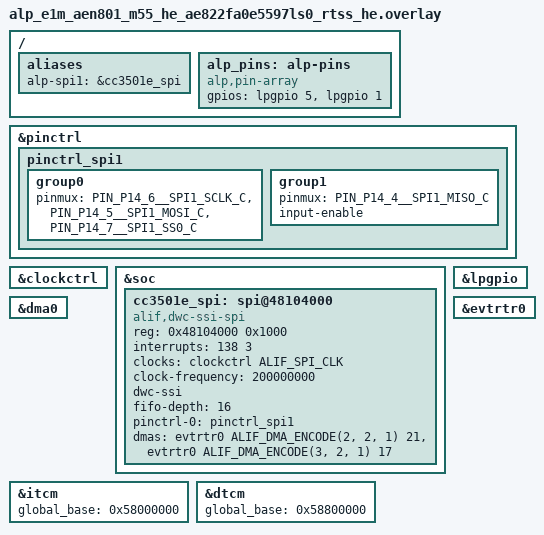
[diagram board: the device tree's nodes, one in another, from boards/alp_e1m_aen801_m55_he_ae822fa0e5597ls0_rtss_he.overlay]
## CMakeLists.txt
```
# SPDX-License-Identifier: Apache-2.0

cmake_minimum_required(VERSION 3.20)

find_package(Zephyr REQUIRED HINTS $ENV{ZEPHYR_BASE})
project(aen_cc3501e_ble_gatt LANGUAGES C)

target_sources(app PRIVATE src/main.c)
# Reusable SoM bring-up helper (cc3501e_bridge_bringup): the one-call CC3501E
# bridge init the example + applications use.  Copied VERBATIM from
# aen-cc3501e-companion-tour -- see cc3501e_bridge.h for why it's a
# copyable template.
target_sources(app PRIVATE src/cc3501e_bridge.c)
```

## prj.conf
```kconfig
# SPDX-License-Identifier: Apache-2.0
#
# CONFIG_SPI / CONFIG_GPIO / CONFIG_ALP_SDK_BLE_CC3501E are pulled in from
# board.yaml's `peripherals:` / `cores.m55_he.iot.ble:` blocks (via the
# generated alp.conf); this file carries only what board.yaml can't express.
CONFIG_PRINTK=y
CONFIG_LOG=y

# The bench proof issues a handful of BLE calls + a couple of gatt buffers;
# no sockets/DMA-stream scratch like the companion-tour, so the default
# tour-sized stack is generous headroom, not a tuned minimum.
CONFIG_MAIN_STACK_SIZE=4096

# Link the app at the HE MRAM app partition (0x80010000) so its vector table
# matches the ATOC load address (app-zephyr-he.json mramAddress=0x80010000).
# FLASH_BASE is the full MRAM (0x80000000); without this 0x10000 offset the
# image links at 0x80000000 and the SES boots it 64 KB low -> fault/no-boot.
CONFIG_FLASH_LOAD_OFFSET=0x10000
```

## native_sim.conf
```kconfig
# SPDX-License-Identifier: Apache-2.0
#
# native_sim overlay, layered in via the testcase.yaml
# `extra_args: EXTRA_CONF_FILE=native_sim.conf` so it applies AFTER the
# generated alp.conf (a boards/*.conf is applied BEFORE EXTRA_CONF_FILE and
# therefore cannot override the generated console -- this file can; same
# mechanism audio-noise-suppression uses to override generated CONFIG_I2S).
#
# board.yaml sets `diagnostics.console: ram` (the bench RAM console, a
# real-silicon / no-USB-UART artifact). On native_sim CONFIG_RAM_CONSOLE
# pulls picolibc's __stdout_hook_install, which the native/host console does
# not provide, so the link fails with an undefined reference. Use the native
# UART console off-target -- the only point of this build_only scenario is
# that the portable <alp/ble.h> GATT-server path compiles + links.
CONFIG_RAM_CONSOLE=n
CONFIG_UART_CONSOLE=y
```

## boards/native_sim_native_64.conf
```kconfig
# SPDX-License-Identifier: Apache-2.0
#
# native_sim has no real SPI controller; pull in the emul SPI driver so
# the alp-spi1 bus enumerates at boot.  Auto-loaded by Zephyr when
# building for native_sim/native/64.  (On the real AEN board the alp-spi1
# alias resolves to the dwc-ssi SPI1 controller instead -- see
# boards/alp_e1m_aen801_m55_he.overlay.)

CONFIG_EMUL=y
CONFIG_SPI_EMUL=y

# NB: the native_sim RAM-console override is NOT here -- a boards/*.conf is
# applied BEFORE EXTRA_CONF_FILE (the generated alp.conf, which sets
# CONFIG_RAM_CONSOLE=y from board.yaml), so it cannot win. The console
# override lives in ../native_sim.conf, layered AFTER alp.conf via the
# testcase.yaml `extra_args: EXTRA_CONF_FILE=native_sim.conf`.
```

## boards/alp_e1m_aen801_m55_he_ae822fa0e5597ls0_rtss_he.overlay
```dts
/*
 * Copyright (c) 2026 Alp Lab AB
 * SPDX-License-Identifier: Apache-2.0
 *
 * Inter-chip wiring for the CC3501E bring-up on the E1M-AEN801 (Alif
 * Ensemble E8, M55-HE).  Declares the SoM-internal Alif<->CC3501E link:
 * the SPI1 master bus + the two host-driven control nets, all from
 * metadata/e1m_modules/aen/inter-chip.tsv:
 *
 *   SPI1.SCK  P14_6   SPI1.MOSI P14_5   SPI1.MISO P14_4   (-> CC3501E GPIO_27/28/29)
 *   WIFI_EN   P15_5 (lpgpio 5)          E_WIFI.NRST P15_1_FLEX (lpgpio 1)
 *
 * "P15" is the Alif low-power GPIO island (lpgpio @ 0x42002000); the
 * _FLEX pads are its pins.  P14 is a main-domain port used here purely as
 * the SPI1 function via pinctrl, so no gpio14 controller node is needed.
 *
 * BENCH-UNVERIFIED.  Like the rest of the alp-sdk Alif peripheral layer
 * (zephyr/dts/alif/ensemble_e8_peripherals.dtsi), the addresses/IRQs are
 * transcribed from the Apache-2.0 alifsemi/zephyr_alif fork + the AE822
 * TRM and have NOT been validated on silicon.  The SPI1 pinctrl macros are
 * RESOLVED against zephyr/dt-bindings/pinctrl/alif-ensemble-pinctrl.h
 * (SPI1 on P14_4/5/6 = alt-2, the `_C` suffix) and the LP-GPIO mux is the
 * reset default (alt-0 = LPGPIO); the one remaining genuine unknown is the
 * SPI1 IRQ number (upstream Zephyr declares no SPI node, so it is not in
 * the build tree) -- confirm it against the AE822 TRM before relying on
 * the interrupt-driven path on silicon.
 */

#include <zephyr/dt-bindings/pinctrl/alif-ensemble-pinctrl.h>
#include <zephyr/dt-bindings/gpio/gpio.h>
#include <zephyr/dt-bindings/dma/alif_dma_event_router.h>

&pinctrl {
	/*
	 * SPI1 master on P14_6 (SCK) / P14_5 (MOSI) / P14_4 (MISO).
	 *
	 * RESOLVED against alif-ensemble-pinctrl.h: the SPI1 functions on these
	 * three pads are alt-2, named with the `_C` suffix
	 * (PIN_P14_6__SPI1_SCLK_C = ALIF_PINMUX(14, 6, 2), etc.).  input-enable
	 * on MISO so the pad can sense the slave's drive (the same read-enable
	 * requirement the I2C pads need on this SoC).
	 */
	pinctrl_spi1: pinctrl_spi1 {
		group0 {
			/* Hardware SS0 chip-select (P14_7 = SPI1_SS0_C) -- dwc-ssi master
			 * drives SS0 per transfer to frame the CC3501E slave. */
			pinmux = <PIN_P14_6__SPI1_SCLK_C>, <PIN_P14_5__SPI1_MOSI_C>,
				 <PIN_P14_7__SPI1_SS0_C>;
		};
		group1 {
			pinmux = <PIN_P14_4__SPI1_MISO_C>;
			input-enable;
		};
	};
};

/*
 * DWC_ssi SPI1 (AHB) -- the on-SoM CC3501E inter-chip link.  Deliberately
 * NOT in ensemble_e8_peripherals.dtsi (that dtsi declares only the
 * customer-facing edge SPI0); this is the SoM-internal Wi-Fi link, so it
 * lives in the consuming app's overlay.  Same driver + flags as spi0
 * (compatible "alif,dwc-ssi-spi", dwc-ssi layout, fifo-depth 16,
 * frequency-only ALIF_SPI_CLK).
 *
 * reg 0x48104000 = SPI1 base (spi0 is 0x48103000, +0x1000/instance).
 * BENCH-TBD: interrupts = <138 3> follows the consecutive pattern from
 * spi0's IRQ 137 -- confirm SPI1_IRQ against the fork's e1.dtsi / TRM.
 *
 * No cs-gpios: P14_7 is muxed as SPI1_SS0_C above and the dwc-ssi peripheral
 * drives hardware SS0 per transfer.  The host opens ALP_SPI_NO_CS so no GPIO CS
 * is installed, allowing the SPI driver to use its hardware slave-select path.
 */
&clockctrl {
	status = "okay";
};

&soc {
	cc3501e_spi: spi@48104000 {
		compatible = "alif,dwc-ssi-spi";
		#address-cells = <1>;
		#size-cells = <0>;
		reg = <0x48104000 0x1000>;
		interrupts = <138 3>;          /* BENCH-TBD: confirm SPI1 IRQ */
		clocks = <&clockctrl ALIF_SPI_CLK>;
		/*
		 * ROOT-CAUSE FIX 2026-06-16: spi_dw_alif's configure takes the
		 * clock-control path when no clock-frequency is set, and that path
		 * fails (-EINVAL) for the gateless dummy ALIF_SPI_CLK -> every
		 * transceive returned ALP_ERR_INVAL with zero SCLK (witness fail_step=1,
		 * zerr=-EINVAL). Providing the SSI input clock here makes the driver
		 * use it directly and skip the failing clock-control path. The real
		 * SSI functional clock (E8 HWRM) is 200 MHz, not the 400 MHz AHB/
		 * SYST_HCLK rate; BAUDR = 200M/freq_hz (=25 for an 8 MHz SCLK).
		 */
		clock-frequency = <200000000>; /* real SSI functional clock (was mis-set 400M; proven via BAUDR scaling) */
		dwc-ssi;
		fifo-depth = <16>;
		pinctrl-0 = <&pinctrl_spi1>;
		pinctrl-names = "default";
		status = "okay";
	};
};

/*
 * Enable the LP GPIO island so WIFI_EN (P15_5) and E_WIFI.NRST
 * (P15_1_FLEX) are drivable as outputs.  gpio_dw needs no clocks/pinctrl
 * on the controller, and the pad->GPIO mux needs no pinctrl group either:
 * RESOLVED against alif-ensemble-pinctrl.h -- P15_1/P15_5 function 0 (the
 * reset default) IS LPGPIO (PIN_P15_x__LPGPIO = ALIF_PINMUX(15, x, 0)).
 */
&lpgpio {
	status = "okay";
};

/* P2_6 (E1M AH7 / I2S1_SCLK) is NOT the CC3501E READY net on the R2 module this
 * bridge targets -- it is E1M pad AH7 / I2S1_SCLK, which the E1M EVK carrier
 * repurposes as the Arduino header's CK_RST (metadata/boards/e1m-evk.yaml);
 * the real READY net lands on E1M pad G3 / IO16 instead
 * (metadata/e1m_modules/aen/from-cc3501e.tsv). This app therefore does not
 * enable &gpio2 or claim P2_6 as READY -- see src/cc3501e_bridge.c and
 * chips/cc3501e/cc3501e_core.c's cc3501e_reply_gate() comment. A board (or a
 * hand-reworked r1 unit) that genuinely wires GPIO17 to P2_6 can opt back
 * in: enable &gpio2, add a pinctrl group that enables P2_6's INPUT BUFFER --
 * reset-default mux already IS GPIO, but GPIO function alone does not enable
 * the input path; skip that group and cc3501e_reply_gate()'s read comes back
 * a constant 0 forever, indistinguishable from a stuck-LOW pad -- add an
 * alp_pins entry for it, and set fw->ready_pin in cc3501e_bridge_bringup(). */

/*
 * Host-side peripheral DMA for continuous SPI streams over the CC3501E bridge.
 * SPI1 is a MAIN-domain peripheral, so per the AE822 DFP soc_dma_map (SPI1_DMA=0,
 * group 2, TX req 21 / RX req 17) it routes through the SYSTOP DMA0 via its event
 * router evtrtr0 (4 groups -> group 2 valid) -- NOT the M55-HE-local DMA2/evtrtr2
 * (1 group, for LP peripherals; wiring SPI1 there leaves the channel Waiting-For-
 * Peripheral forever -- SPI1's request line isn't on the HE router).  DMA0's clock
 * is SYSTOP (already on -- the app drives SPI1/GPIO in the same region); its
 * PL330 boot-manager security latch (CLKCTRL_PER_MST) is in dma_alif_boot_latch.c.
 * The fork PL330 driver statically allocates the per-channel ucode + remaps it via
 * local_to_global(), so no external `microcode` prop is needed.
 *
 * dma0 + evtrtr0 are now declared in ensemble_e8_peripherals.dtsi (disabled
 * by default, alp-sdk issue #1815); this overlay only enables them.
 */
&dma0 {
	status = "okay";
};

&evtrtr0 {
	status = "okay";
};

/*
 * Route the bridge SPI1 through evtrtr0 to DMA0.  Cell encoding
 * (ALIF_DMA_ENCODE(channel, dma_group, handshake), periph_req):
 *   TX = PL330 ch2, evtrtr group 2, handshake on, SPI1 TX periph req 21
 *   RX = PL330 ch3, evtrtr group 2, handshake on, SPI1 RX periph req 17
 * (AE822 DFP soc_dma_map.h: SPI1 group 2, TX 21 / RX 17.)
 */
&cc3501e_spi {
	dmas = <&evtrtr0 ALIF_DMA_ENCODE(2, 2, 1) 21>,
	       <&evtrtr0 ALIF_DMA_ENCODE(3, 2, 1) 17>;
	dma-names = "txdma", "rxdma";
};

/ {
	aliases {
		/* bus_id 1 in alp_spi_open() -> this controller. */
		alp-spi1 = &cc3501e_spi;
	};

	/*
	 * Compact 2-entry control array for the SoM-internal CC3501E control
	 * nets, in the order the app's CC3501E_PIN_* indices expect.  These are
	 * NOT E1M edge pads, so this bring-up app intentionally does NOT use the
	 * 52-slot positional E1M map; a production board file appends such
	 * SoM-internal control nets after the E1M pad slots.  No READY entry
	 * here -- see the P2_6 comment above &gpio2's removal further up.
	 */
	alp_pins: alp-pins {
		compatible = "alp,pin-array";
		gpios = <&lpgpio 5 GPIO_ACTIVE_HIGH>, /* [0] WIFI_EN     (P15_5)      */
			<&lpgpio 1 GPIO_ACTIVE_HIGH>; /* [1] E_WIFI.NRST (P15_1_FLEX) */
	};
};

/*
 * Global-bus aliases of the M55-HE TCMs, needed by hal_alif soc_memory_map.h
 * local_to_global() -- the PL330 (AXI master) reaches TCM-resident buffers only
 * via these global windows.  Values from the AE822 M55-HE map (sdk-alif fork
 * ensemble_rtss_he.dtsi): ITCM 0x0->0x58000000, DTCM 0x20000000->0x58800000.
 * (DMA stream buffers still belong in SRAM0 0x02000000, which is already global
 * -> local_to_global() returns it unchanged.)
 */
&itcm {
	global_base = <0x58000000>;
};
&dtcm {
	global_base = <0x58800000>;
};
```

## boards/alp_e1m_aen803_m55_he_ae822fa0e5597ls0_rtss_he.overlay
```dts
/*
 * Copyright (c) 2026 Alp Lab AB
 * SPDX-License-Identifier: Apache-2.0
 *
 * Inter-chip wiring for the CC3501E bring-up on the E1M-AEN803 (Alif
 * Ensemble E8, M55-HE).  Declares the SoM-internal Alif<->CC3501E link:
 * the SPI1 master bus + the two host-driven control nets, all from
 * metadata/e1m_modules/aen/inter-chip.tsv:
 *
 *   SPI1.SCK  P14_6   SPI1.MOSI P14_5   SPI1.MISO P14_4   (-> CC3501E GPIO_27/28/29)
 *   WIFI_EN   P15_5 (lpgpio 5)          E_WIFI.NRST P15_1_FLEX (lpgpio 1)
 *
 * "P15" is the Alif low-power GPIO island (lpgpio @ 0x42002000); the
 * _FLEX pads are its pins.  P14 is a main-domain port used here purely as
 * the SPI1 function via pinctrl, so no gpio14 controller node is needed.
 *
 * BENCH-UNVERIFIED.  Like the rest of the alp-sdk Alif peripheral layer
 * (zephyr/dts/alif/ensemble_e8_peripherals.dtsi), the addresses/IRQs are
 * transcribed from the Apache-2.0 alifsemi/zephyr_alif fork + the AE822
 * TRM and have NOT been validated on silicon.  The SPI1 pinctrl macros are
 * RESOLVED against zephyr/dt-bindings/pinctrl/alif-ensemble-pinctrl.h
 * (SPI1 on P14_4/5/6 = alt-2, the `_C` suffix) and the LP-GPIO mux is the
 * reset default (alt-0 = LPGPIO); the one remaining genuine unknown is the
 * SPI1 IRQ number (upstream Zephyr declares no SPI node, so it is not in
 * the build tree) -- confirm it against the AE822 TRM before relying on
 * the interrupt-driven path on silicon.
 */

#include <zephyr/dt-bindings/pinctrl/alif-ensemble-pinctrl.h>
#include <zephyr/dt-bindings/gpio/gpio.h>
#include <zephyr/dt-bindings/dma/alif_dma_event_router.h>

&pinctrl {
	/*
	 * SPI1 master on P14_6 (SCK) / P14_5 (MOSI) / P14_4 (MISO).
	 *
	 * RESOLVED against alif-ensemble-pinctrl.h: the SPI1 functions on these
	 * three pads are alt-2, named with the `_C` suffix
	 * (PIN_P14_6__SPI1_SCLK_C = ALIF_PINMUX(14, 6, 2), etc.).  input-enable
	 * on MISO so the pad can sense the slave's drive (the same read-enable
	 * requirement the I2C pads need on this SoC).
	 */
	pinctrl_spi1: pinctrl_spi1 {
		group0 {
			/* Hardware SS0 chip-select (P14_7 = SPI1_SS0_C) -- dwc-ssi master
			 * drives SS0 per transfer to frame the CC3501E slave. */
			pinmux = <PIN_P14_6__SPI1_SCLK_C>, <PIN_P14_5__SPI1_MOSI_C>,
				 <PIN_P14_7__SPI1_SS0_C>;
		};
		group1 {
			pinmux = <PIN_P14_4__SPI1_MISO_C>;
			input-enable;
		};
	};
};

/*
 * DWC_ssi SPI1 (AHB) -- the on-SoM CC3501E inter-chip link.  Deliberately
 * NOT in ensemble_e8_peripherals.dtsi (that dtsi declares only the
 * customer-facing edge SPI0); this is the SoM-internal Wi-Fi link, so it
 * lives in the consuming app's overlay.  Same driver + flags as spi0
 * (compatible "alif,dwc-ssi-spi", dwc-ssi layout, fifo-depth 16,
 * frequency-only ALIF_SPI_CLK).
 *
 * reg 0x48104000 = SPI1 base (spi0 is 0x48103000, +0x1000/instance).
 * BENCH-TBD: interrupts = <138 3> follows the consecutive pattern from
 * spi0's IRQ 137 -- confirm SPI1_IRQ against the fork's e1.dtsi / TRM.
 *
 * No cs-gpios: P14_7 is muxed as SPI1_SS0_C above and the dwc-ssi peripheral
 * drives hardware SS0 per transfer.  The host opens ALP_SPI_NO_CS so no GPIO CS
 * is installed, allowing the SPI driver to use its hardware slave-select path.
 */
&clockctrl {
	status = "okay";
};

&soc {
	cc3501e_spi: spi@48104000 {
		compatible = "alif,dwc-ssi-spi";
		#address-cells = <1>;
		#size-cells = <0>;
		reg = <0x48104000 0x1000>;
		interrupts = <138 3>;          /* BENCH-TBD: confirm SPI1 IRQ */
		clocks = <&clockctrl ALIF_SPI_CLK>;
		/*
		 * ROOT-CAUSE FIX 2026-06-16: spi_dw_alif's configure takes the
		 * clock-control path when no clock-frequency is set, and that path
		 * fails (-EINVAL) for the gateless dummy ALIF_SPI_CLK -> every
		 * transceive returned ALP_ERR_INVAL with zero SCLK (witness fail_step=1,
		 * zerr=-EINVAL). Providing the SSI input clock here makes the driver
		 * use it directly and skip the failing clock-control path. The real
		 * SSI functional clock (E8 HWRM) is 200 MHz, not the 400 MHz AHB/
		 * SYST_HCLK rate; BAUDR = 200M/freq_hz (=25 for an 8 MHz SCLK).
		 */
		clock-frequency = <200000000>; /* real SSI functional clock (was mis-set 400M; proven via BAUDR scaling) */
		dwc-ssi;
		fifo-depth = <16>;
		pinctrl-0 = <&pinctrl_spi1>;
		pinctrl-names = "default";
		status = "okay";
	};
};

/*
 * Enable the LP GPIO island so WIFI_EN (P15_5) and E_WIFI.NRST
 * (P15_1_FLEX) are drivable as outputs.  gpio_dw needs no clocks/pinctrl
 * on the controller, and the pad->GPIO mux needs no pinctrl group either:
 * RESOLVED against alif-ensemble-pinctrl.h -- P15_1/P15_5 function 0 (the
 * reset default) IS LPGPIO (PIN_P15_x__LPGPIO = ALIF_PINMUX(15, x, 0)).
 */
&lpgpio {
	status = "okay";
};

/* P2_6 (E1M AH7 / I2S1_SCLK) is NOT the CC3501E READY net on the R2 module this
 * bridge targets -- it is E1M pad AH7 / I2S1_SCLK, which the E1M EVK carrier
 * repurposes as the Arduino header's CK_RST (metadata/boards/e1m-evk.yaml);
 * the real READY net lands on E1M pad G3 / IO16 instead
 * (metadata/e1m_modules/aen/from-cc3501e.tsv). This app therefore does not
 * enable &gpio2 or claim P2_6 as READY -- see src/cc3501e_bridge.c and
 * chips/cc3501e/cc3501e_core.c's cc3501e_reply_gate() comment. A board (or a
 * hand-reworked r1 unit) that genuinely wires GPIO17 to P2_6 can opt back
 * in: enable &gpio2, add a pinctrl group that enables P2_6's INPUT BUFFER --
 * reset-default mux already IS GPIO, but GPIO function alone does not enable
 * the input path; skip that group and cc3501e_reply_gate()'s read comes back
 * a constant 0 forever, indistinguishable from a stuck-LOW pad -- add an
 * alp_pins entry for it, and set fw->ready_pin in cc3501e_bridge_bringup(). */

/*
 * Host-side peripheral DMA for continuous SPI streams over the CC3501E bridge.
 * SPI1 is a MAIN-domain peripheral, so per the AE822 DFP soc_dma_map (SPI1_DMA=0,
 * group 2, TX req 21 / RX req 17) it routes through the SYSTOP DMA0 via its event
 * router evtrtr0 (4 groups -> group 2 valid) -- NOT the M55-HE-local DMA2/evtrtr2
 * (1 group, for LP peripherals; wiring SPI1 there leaves the channel Waiting-For-
 * Peripheral forever -- SPI1's request line isn't on the HE router).  DMA0's clock
 * is SYSTOP (already on -- the app drives SPI1/GPIO in the same region); its
 * PL330 boot-manager security latch (CLKCTRL_PER_MST) is in dma_alif_boot_latch.c.
 * The fork PL330 driver statically allocates the per-channel ucode + remaps it via
 * local_to_global(), so no external `microcode` prop is needed.
 *
 * dma0 + evtrtr0 are now declared in ensemble_e8_peripherals.dtsi (disabled
 * by default, alp-sdk issue #1815); this overlay only enables them.
 */
&dma0 {
	status = "okay";
};

&evtrtr0 {
	status = "okay";
};

/*
 * Route the bridge SPI1 through evtrtr0 to DMA0.  Cell encoding
 * (ALIF_DMA_ENCODE(channel, dma_group, handshake), periph_req):
 *   TX = PL330 ch2, evtrtr group 2, handshake on, SPI1 TX periph req 21
 *   RX = PL330 ch3, evtrtr group 2, handshake on, SPI1 RX periph req 17
 * (AE822 DFP soc_dma_map.h: SPI1 group 2, TX 21 / RX 17.)
 */
&cc3501e_spi {
	dmas = <&evtrtr0 ALIF_DMA_ENCODE(2, 2, 1) 21>,
	       <&evtrtr0 ALIF_DMA_ENCODE(3, 2, 1) 17>;
	dma-names = "txdma", "rxdma";
};

/ {
	aliases {
		/* bus_id 1 in alp_spi_open() -> this controller. */
		alp-spi1 = &cc3501e_spi;
	};

	/*
	 * Compact 2-entry control array for the SoM-internal CC3501E control
	 * nets, in the order the app's CC3501E_PIN_* indices expect.  These are
	 * NOT E1M edge pads, so this bring-up app intentionally does NOT use the
	 * 52-slot positional E1M map; a production board file appends such
	 * SoM-internal control nets after the E1M pad slots.  No READY entry
	 * here -- see the P2_6 comment above &gpio2's removal further up.
	 */
	alp_pins: alp-pins {
		compatible = "alp,pin-array";
		gpios = <&lpgpio 5 GPIO_ACTIVE_HIGH>, /* [0] WIFI_EN     (P15_5)      */
			<&lpgpio 1 GPIO_ACTIVE_HIGH>; /* [1] E_WIFI.NRST (P15_1_FLEX) */
	};
};

/*
 * Global-bus aliases of the M55-HE TCMs, needed by hal_alif soc_memory_map.h
 * local_to_global() -- the PL330 (AXI master) reaches TCM-resident buffers only
 * via these global windows.  Values from the AE822 M55-HE map (sdk-alif fork
 * ensemble_rtss_he.dtsi): ITCM 0x0->0x58000000, DTCM 0x20000000->0x58800000.
 * (DMA stream buffers still belong in SRAM0 0x02000000, which is already global
 * -> local_to_global() returns it unchanged.)
 */
&itcm {
	global_base = <0x58000000>;
};
&dtcm {
	global_base = <0x58800000>;
};
```

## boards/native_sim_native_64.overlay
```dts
/*
 * Copyright 2026 Alp Lab AB
 * SPDX-License-Identifier: Apache-2.0
 *
 * Host-emulated stand-ins for aen-cc3501e-ble-gatt under native_sim, so the
 * example builds in CI (twister build_only) with no silicon.
 *
 *   - alp-spi1  -> an emulated SPI controller (no slave attached, so the
 *                  transceive path runs but reads back 0x00; the build, not
 *                  a live round-trip, is what this target proves).
 *   - alp,pin-array -> the two SoM-internal CC3501E control nets, in the
 *                  SAME order the app's CC3501E_PIN_* indices expect:
 *                    [0] WIFI_EN  (Alif P15_5)
 *                    [1] E_WIFI.NRST (Alif P15_1_FLEX)
 *                  This bring-up app uses its own compact 2-pin control
 *                  array (these nets are not E1M edge pads), not the 52-slot
 *                  positional E1M map the portable IO examples use.
 */

#include <zephyr/dt-bindings/gpio/gpio.h>

/ {
    aliases {
        alp-spi1 = &spi1_emul;
    };

    gpio_emul0: gpio_emul0 {
        compatible = "zephyr,gpio-emul";
        status = "okay";
        gpio-controller;
        rising-edge;
        falling-edge;
        #gpio-cells = <2>;
        ngpios = <8>;
    };

    alp_pins: alp-pins {
        compatible = "alp,pin-array";
        gpios = <&gpio_emul0 5 GPIO_ACTIVE_HIGH>,   /* [0] WIFI_EN     (P15_5)      */
                <&gpio_emul0 1 GPIO_ACTIVE_HIGH>;   /* [1] E_WIFI.NRST (P15_1_FLEX) */
    };

    soc {
        spi1_emul: spi@200 {
            compatible = "zephyr,spi-emul-controller";
            status = "okay";
            reg = <0 0x200 4>;
            #address-cells = <1>;
            #size-cells = <0>;
        };
    };
};
```

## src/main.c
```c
/*
 * Copyright 2026 Alp Lab AB
 * SPDX-License-Identifier: Apache-2.0
 *
 * aen-cc3501e-ble-gatt -- bench proof of the #480 CC3501E BLE GATT-SERVER
 * path through the PORTABLE <alp/ble.h> surface, on the E1M-AEN801 (Alif
 * Ensemble E8, M55-HE).
 *
 * WHAT THIS PROVES.  <alp/ble.h> is backend-dispatched (src/ble_dispatch.c):
 * on AEN, alp_ble_open() selects src/backends/ble/cc3501e.c, which forwards
 * every call over the inter-chip SPI1 bridge to the TI CC3501E's OWN
 * Cortex-M33 -- the CC35 runs the real BLE controller + NimBLE host, not the
 * Alif.  So "the portable GATT path" here means: app calls alp_ble_*() ->
 * ble_dispatch.c -> backends/ble/cc3501e.c -> chips/cc3501e/ble.h wire
 * commands (<alp/protocol/cc3501e.h> opcodes 0x30..0x3B) -> the CC35
 * firmware.  It is a full-stack coprocessor bridge, NOT a bare HCI
 * controller the Alif drives directly.
 *
 * SERVER-ONLY, NO LIVE CENTRAL PEER ON THIS BENCH.  There is no second BLE
 * device in range to connect to, so this app never calls alp_ble_connect().
 * That shapes the PASS contract below in a way worth reading carefully
 * BEFORE assuming a non-ALP_OK return means something is broken:
 *
 *   1. alp_ble_open()               -- expect non-NULL.  Internally routes
 *      through cc35_open() (backends/ble/cc3501e.c:86-104), which calls
 *      cc3501e_ble_enable() -- a REAL wire round-trip (BLE_ENABLE, 0x30)
 *      that brings the CC35's Wi-Fi stack + NimBLE host up.
 *
 *   2. alp_ble_gatt_register_service() -- expect ALP_OK with both attribute
 *      handles non-zero, not NOSUPPORT.  cc35_gatt_register_service()
 *      (backends/ble/cc3501e.c:145-...) is no longer a stub as of #892: it
 *      really encodes the service over the wire (BLE_GATT_REGISTER, 0x38)
 *      and the CC35's NimBLE host really registers it, handing back a real
 *      per-characteristic attribute handle.  Getting ALP_OK with non-zero
 *      handles back -- not a hang, not a silently-wrong handle -- IS the
 *      proof that the portable dispatch reaches the real CC3501E backend and
 *      that backend actually registered the service (see
 *      aen-cc3501e-gatt-register for the dedicated, deeper bench proof of
 *      this path, including the register-while-advertising ordering guard).
 *
 *   3. alp_ble_advertise_start() -- expect ALP_OK.  This is the one call in
 *      this app that is a genuine over-the-bridge wire round-trip to
 *      firmware that already exists end to end (BLE_ADV_START, 0x32,
 *      chips/cc3501e/ble.h) -- the real "on silicon" proof leg.
 *
 *   4. gatt_read / gatt_write / gatt_notify -- called with a NULL
 *      alp_ble_conn_t* (there is no connection to pass: <alp/ble.h> models
 *      these as PEER-scoped ops taken over a connection returned by
 *      alp_ble_connect(), and central-role connect is out of scope on a
 *      server-only, no-peer bench -- see chips/cc3501e/ble.h's
 *      cc3501e_ble_gatt_read/write, documented as needing "BLE enabled +
 *      CONNECTED").  Calling them anyway with conn=NULL is the "local"
 *      exercise the task asks for: it proves the dispatcher's
 *      connection-handle guard (src/ble_dispatch.c) rejects the call
 *      BEFORE it ever reaches the wire, with the exact documented status,
 *      rather than crashing on a NULL deref or blocking forever:
 *        - gatt_read(NULL, ...)  -> ALP_ERR_NOT_READY  (ble_dispatch.c: c
 *          == NULL fails alp_handle_op_enter up front)
 *        - gatt_write(NULL, ...) -> ALP_ERR_NOT_READY  (same guard)
 *        - gatt_notify(ble, NULL, ...) -> ALP_ERR_INVAL (ble_dispatch.c
 *          checks `conn == NULL` explicitly and returns INVAL, a
 *          DIFFERENT code from the read/write guard -- both are asserted
 *          below so a future dispatch refactor that blurs them is caught)
 *      A full read/write ECHO against a live central is explicitly
 *      HIL-deferred: it needs a second BLE peer on the bench, which this
 *      single-board setup does not have.
 *
 * This file is ~50% comment by design: examples are documentation.
 */

#include <stdio.h>
#include <stdbool.h>
#include <string.h>

#include "alp/ble.h"
#include "alp/chips/cc3501e.h"
#include "alp/peripheral.h"

#include "cc3501e_bridge.h" /* cc3501e_bridge_bringup() -- the SoM bring-up helper */

/* Poll-by-repeat budget for the first PING: reset() already waited out the
 * boot budget, so this just absorbs residual ramp/boot jitter (same
 * constants as aen-cc3501e-bringup / aen-cc3501e-companion-tour). */
#define GATT_PING_RETRIES 25u
#define GATT_PING_GAP_MS  200u

/* Caller budget passed to the local (no-peer) gatt_read/write calls below.
 * It is never actually waited out: both calls reject on the NULL conn
 * before any timeout-driven wait starts (see the file header). Kept
 * non-zero anyway so the call shape matches a real central-role caller's. */
#define GATT_LOCAL_OP_TIMEOUT_MS 2000u

/*
 * Example/test-only UUIDs -- NOT allocated from the BT-SIG / a real vendor
 * range.  A production service must use a UUID it actually owns (a 16-bit
 * SIG-assigned UUID, or a 128-bit UUID generated for the product).
 */
static const alp_ble_uuid_t GATT_SVC_UUID   = { .b = { 0xA1,
	                                                   0xB0,
	                                                   0xE1,
	                                                   0x60,
	                                                   0x00,
	                                                   0x01,
	                                                   0x00,
	                                                   0x02,
	                                                   0x00,
	                                                   0x03,
	                                                   0x00,
	                                                   0x04,
	                                                   0x00,
	                                                   0x05,
	                                                   0x00,
	                                                   0x01 } };
static const alp_ble_uuid_t GATT_CHAR1_UUID = { .b = { 0xA1,
	                                                   0xB0,
	                                                   0xE1,
	                                                   0x60,
	                                                   0x00,
	                                                   0x01,
	                                                   0x00,
	                                                   0x02,
	                                                   0x00,
	                                                   0x03,
	                                                   0x00,
	                                                   0x04,
	                                                   0x00,
	                                                   0x05,
	                                                   0x00,
	                                                   0x02 } };
static const alp_ble_uuid_t GATT_CHAR2_UUID = { .b = { 0xA1,
	                                                   0xB0,
	                                                   0xE1,
	                                                   0x60,
	                                                   0x00,
	                                                   0x01,
	                                                   0x00,
	                                                   0x02,
	                                                   0x00,
	                                                   0x03,
	                                                   0x00,
	                                                   0x04,
	                                                   0x00,
	                                                   0x05,
	                                                   0x00,
	                                                   0x03 } };

/* Track pass/fail across the checkpoints below so main() can print one
 * RESULT PASS:/RESULT FAIL: line at the end (the bench-observable contract
 * -- see flashing-and-bench-debugging-aen's "how to verify" section). */
static unsigned g_fail_count;

/* Print + tally one checkpoint.  `what` names the call, `got` is its
 * return, `want` is the value THIS bench (server-only, no live peer) is
 * expected to see -- see the file header for why several of these are
 * deliberately not ALP_OK. */
static void gatt_check(const char *what, alp_status_t got, alp_status_t want)
{
	if (got == want) {
		printf("[gatt] %-24s -> %s (expected)\n", what, alp_status_name(got));
	} else {
		printf("[gatt] %-24s -> %s (expected %s)\n",
		       what,
		       alp_status_name(got),
		       alp_status_name(want));
		g_fail_count++;
	}
}

int main(void)
{
	printf("\n[gatt] E1M-AEN CC3501E BLE GATT-SERVER bench proof (#480, server-only, no peer)\n");

	/*
	 * Step 1 -- SoM bring-up (control pins + inter-chip SPI + power/reset),
	 * ONE call: cc3501e_bridge_bringup() (cc3501e_bridge.{c,h}, the same
	 * reusable template aen-cc3501e-bringup / -companion-tour use).
	 */
	cc3501e_t    fw;
	alp_status_t s = cc3501e_bridge_bringup(&fw);
	if (s != ALP_OK) {
		printf("RESULT FAIL: cc3501e_bridge_bringup -> %s (check the board overlay / "
		       "WIFI_EN+nRESET wiring)\n",
		       alp_status_name(s));
		return 0;
	}
	printf("[gatt] bridge bring-up -> %s\n", alp_status_name(s));

	/* Step 2 -- liveness.  A serviced PING proves the firmware parsed a
	 * frame and staged its reply over the hardware-framed bridge -- the
	 * gate every later step depends on. */
	bool linked = false;
	for (unsigned attempt = 0u; attempt < GATT_PING_RETRIES; ++attempt) {
		if (cc3501e_ping(&fw) == ALP_OK) {
			printf("[gatt] PING ok after %u attempt%s\n", attempt + 1u, (attempt == 0u) ? "" : "s");
			linked = true;
			break;
		}
		alp_delay_ms(GATT_PING_GAP_MS);
	}
	if (!linked) {
		printf("RESULT FAIL: coprocessor never answered PING -- check power (WIFI_EN), the "
		       "SPI1 pinmux, and that the CC3501E is running its firmware\n");
		return 0;
	}

	/*
	 * Step 3 -- open the portable BLE radio.  On AEN this selects
	 * backends/ble/cc3501e.c, whose open() calls cc3501e_ble_enable()
	 * under the hood (BLE_ENABLE, 0x30) -- a real wire round-trip that
	 * brings the CC35's NimBLE host up.  A non-NULL return covers BOTH
	 * "bridge ready" and "cc3501e_ble_enable OK" from the task's PASS
	 * contract in one checkpoint (that IS the call cc35_open makes).
	 */
	alp_ble_t *ble = alp_ble_open();
	if (ble == NULL) {
		printf("RESULT FAIL: alp_ble_open -> NULL, err=%s (BLE not built into this "
		       "CC3501E firmware image?)\n",
		       alp_status_name(alp_last_error()));
		return 0;
	}
	printf("[gatt] alp_ble_open -> ready (cc3501e_ble_enable succeeded)\n");

	/*
	 * Step 4 -- register a 2-characteristic GATT service via the portable
	 * API.  Expect ALP_OK with both handles non-zero -- see the file header
	 * for why that is the correct, current answer for this backend (#892).
	 */
	static const uint8_t     char1_initial[4] = { 0x00, 0x00, 0x00, 0x00 };
	const alp_ble_char_def_t chars[2]         = {
		{ .uuid          = GATT_CHAR1_UUID,
		  .properties    = ALP_BLE_GATT_PROP_READ | ALP_BLE_GATT_PROP_WRITE,
		  .initial_value = char1_initial,
		  .initial_len   = sizeof(char1_initial) },
		{ .uuid          = GATT_CHAR2_UUID,
		  .properties    = ALP_BLE_GATT_PROP_NOTIFY,
		  .initial_value = NULL,
		  .initial_len   = 0u },
	};
	const alp_ble_service_def_t svc = {
		.service_uuid = GATT_SVC_UUID,
		.chars        = chars,
		.num_chars    = 2u,
	};
	alp_ble_attr_handle_t handles[2] = { 0u, 0u };
	alp_status_t          rc_reg     = alp_ble_gatt_register_service(ble, &svc, handles);
	gatt_check("gatt_register_service", rc_reg, ALP_OK);
	if (rc_reg == ALP_OK && (handles[0] == 0u || handles[1] == 0u)) {
		printf("[gatt] %-24s -> handles=[0x%04x, 0x%04x] (expected both non-zero)\n",
		       "gatt_register_service",
		       handles[0],
		       handles[1]);
		g_fail_count++;
	}

	/*
	 * Step 5 -- start advertising.  Expect ALP_OK: this is the genuine
	 * over-the-bridge silicon proof leg (BLE_ADV_START, 0x32).
	 *
	 * ADV-DATA BUDGET (bench-proven on E1M-AEN801, #480): the CC3501E
	 * BLE_ADV_START wire carries ONE legacy 31-byte advertising payload and
	 * has no scan-response field, so the backend cannot spill the name into a
	 * SCAN_RSP the way a full host stack would -- everything must fit 31 bytes:
	 *   Flags            = 3                (2 hdr + 1, always emitted first)
	 * + Complete Name    = 2 + strlen(name)
	 * + 128-bit UUID     = 2 + 16*num_services
	 * With one service UUID that leaves the name <= 8 chars.  A longer name
	 * overflows and cc3501e.c pack_adv_data() rejects the whole config with
	 * ALP_ERR_INVAL (the first cut of this example used a 15-char name and
	 * FAILED on silicon exactly here).  Keep the service UUID advertised (it is
	 * what a GATT-server proof should announce) and keep the name <= 8.
	 */
	alp_ble_adv_config_t adv = ALP_BLE_ADV_CONFIG_DEFAULT("AenGATT");
	adv.services             = &GATT_SVC_UUID;
	adv.num_services         = 1u;
	alp_status_t rc_adv      = alp_ble_advertise_start(ble, &adv);
	gatt_check("advertise_start", rc_adv, ALP_OK);

	/*
	 * Step 6 -- the "local" gatt read/write/notify exercise: no live
	 * central peer means no alp_ble_conn_t, so these are called with a
	 * NULL conn on purpose (see the file header for exactly which guard
	 * each expected status proves).  handles[0]/[1] ARE real, non-zero
	 * handles from Step 4 now (#892) -- irrelevant here regardless, since
	 * every one of these calls is rejected on the NULL conn before the
	 * handle is ever used.
	 */
	uint8_t      read_buf[32] = { 0 };
	size_t       read_len     = 0u;
	alp_status_t rc_read      = alp_ble_gatt_read(
	    NULL, handles[0], read_buf, sizeof(read_buf), &read_len, GATT_LOCAL_OP_TIMEOUT_MS);
	gatt_check("gatt_read(no conn)", rc_read, ALP_ERR_NOT_READY);

	static const uint8_t write_val[4] = { 0xDE, 0xAD, 0xBE, 0xEF };
	alp_status_t         rc_write     = alp_ble_gatt_write(
	    NULL, handles[0], write_val, sizeof(write_val), GATT_LOCAL_OP_TIMEOUT_MS);
	gatt_check("gatt_write(no conn)", rc_write, ALP_ERR_NOT_READY);

	static const uint8_t notify_val[2] = { 0x01, 0x00 };
	alp_status_t         rc_notify =
	    alp_ble_gatt_notify(ble, NULL, handles[1], notify_val, sizeof(notify_val));
	gatt_check("gatt_notify(no conn)", rc_notify, ALP_ERR_INVAL);

	/* Cleanup.  Not part of the PASS contract (advertising already proved
	 * itself in Step 5); logged for bench visibility only. */
	printf("[gatt] advertise_stop -> %s\n", alp_status_name(alp_ble_advertise_stop(ble)));
	alp_ble_close(ble);

	if (g_fail_count == 0u) {
		printf("RESULT PASS: bridge ready, ble_open ok, register_service OK "
		       "(handles non-zero), advertise_start OK, gatt_read/write/notify all "
		       "correctly rejected with no live peer\n");
	} else {
		printf("RESULT FAIL: %u gatt checkpoint(s) did not match the expected "
		       "server-only/no-peer status -- see [gatt] lines above\n",
		       g_fail_count);
	}
	return 0;
}
```

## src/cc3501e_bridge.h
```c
/*
 * SPDX-License-Identifier: Apache-2.0
 * Copyright 2026 Alp Lab AB
 *
 * One-call bring-up of the E1M-AEN SoM's CC3501E Wi-Fi 6 / BLE coprocessor over the
 * inter-chip SPI bridge -- the SoM bring-up TEMPLATE for applications.
 *
 * The CC3501E is part of the SoM (module U4 = BDE-BW35N): the application does NOT
 * touch the raw SPI bus or the WIFI_EN / nRESET control pins.  It calls
 * cc3501e_bridge_bringup() once, gets a ready @ref cc3501e_t, and from there uses the
 * portable surfaces:
 *   - cc3501e_* (chips/cc3501e)            -- MAC / Wi-Fi / BLE / GPIO-proxy / OTA
 *   - alp_gpio_open(ALP_E1M_GPIO_IOxx)         -- proxied E1M IOs (when the proxy is built)
 *
 * To reuse in your own AEN application: copy this pair (cc3501e_bridge.{c,h}) into your
 * app, or call cc3501e_bridge_bringup() directly.  The bus / pins / clock are the
 * E1M-AEN SoM defaults below; a board variant overrides only those macros -- the SoM
 * stays swappable without touching application code.
 */

#ifndef CC3501E_BRIDGE_H
#define CC3501E_BRIDGE_H

#include <alp/peripheral.h>    /* alp_status_t */
#include <alp/chips/cc3501e.h> /* cc3501e_t */

/* ---- E1M-AEN SoM bridge defaults (override per board variant) ---------------- */

/* Inter-chip SPI: Alif = master, CC3501E = slave.  P14_7 is muxed as the
 * dwc-ssi hardware SS0 chip-select; ALP_SPI_NO_CS means "no software GPIO CS"
 * here, so the controller frames each protocol phase.  Mode 0 matches the
 * CC3501E vendor image frameFormat. */
#ifndef CC3501E_BRIDGE_SPI_BUS_ID
#define CC3501E_BRIDGE_SPI_BUS_ID 1u
#endif
#ifndef CC3501E_BRIDGE_SPI_FREQ_HZ
/* 25 MHz = 200 MHz SSI functional clock / 8.
 *
 * The CC3501E peripheral-mode maximum is 30 MHz, NOT the 15 MHz this comment
 * claimed for most of the bring-up: datasheet SWRS343A section 6.14.2.3.3,
 * `fsclk SPI clock frequency, Peripheral Mode, MAX 30 MHz` (Controller Mode is
 * 40 MHz).  Every earlier ceiling argument here was built on the wrong number.
 *
 * 25 MHz is the fastest LEGAL step available: the DW SSI BAUDR divisor must be
 * EVEN, so from 200 MHz the neighbours are /8 = 25 MHz and /6 = 33.3 MHz, and
 * 33.3 is 11% over the part's maximum.  Reaching exactly 30 MHz would require
 * retargeting the SSI functional clock itself (AE822 HWRM section 8.3.5) --
 * ALIF_SPI_CLK is a frequency-only dummy in the dtsi with no divider control,
 * so there is no software knob for it here.
 *
 * REQUIRES an RX sample delay: at a 40 ns bit period the MISO capture does not
 * land on its own.  That delay comes from CC3501E_BRIDGE_RX_SAMPLE_DLY below --
 * NOT from the SPI node's `rx-delay` property, which the poke in
 * cc3501e_bridge.c overwrites.  The measured working span is in that constant's
 * comment.
 *
 * It does not raise throughput -- silicon-measured
 * 2026-08-24: 682 kB/s at 25 MHz vs 678 kB/s at 14.29 MHz on PIO, 704 vs 701 on
 * DMA, because wire time is only ~554 us of a ~2459 us transaction and the rest
 * is per-frame protocol cost on both ends.  It is worth taking anyway: each
 * transfer occupies the bus for ~44% less time, which is CPU and bus budget
 * handed back to everything else on the SoM.
 *
 * The 14.29 MHz predecessor was scope-confirmed at 14.20-14.26 MHz, which is
 * what validates the 200 MHz functional-clock figure the divider assumes.  A
 * board with longer traces should re-check MISO capture before adopting 25 MHz.
 *
 * SEPARATE, PRE-EXISTING DEFECT (do not blame this clock for it): a bulk read
 * intermittently desyncs partway through -- roughly 1 run in 2-3, at anywhere
 * from 61 kB to 212 kB in -- and then never recovers for the caller's whole
 * retry budget.  It reproduces at 14.29 MHz TOO, so it is not a clock artifact.
 * Signature (host-side, request-header phase of CMD_SOCK_RECV 0x23): the
 * slave's in-band idle marker reads [02 00 00 00] once and then [00 00 00 00]
 * forever instead of A5 A5 A5 A5 -- i.e. the slave is stuck mid-reply on a
 * transfer it armed earlier and never completed.  With
 * SPI_TRANSFER_RETURN_PARTIAL deliberately off, a CS deassert does not complete
 * it, and NEITHER slave self-heal fires (g_resync_count does not move -- the
 * slave is not misframing; g_arm_fail_count does not move -- the arm succeeded).
 * Clocking a full idle frame from the host to satisfy the outstanding count was
 * tried and did NOT recover it.  The fix likely belongs on the slave: a
 * stall watchdog that calls bridge_transport_spi_hw_reinit() when an armed
 * transfer has not completed for N ms. */
#define CC3501E_BRIDGE_SPI_FREQ_HZ 25000000u
#endif

/* CC3501E control pins on the Alif LP-GPIO island (NOT E1M edge pads):
 * WIFI_EN = supply gate (P15_5), nRESET = reset (P15_1_FLEX). */
#ifndef CC3501E_BRIDGE_PIN_WIFI_EN
#define CC3501E_BRIDGE_PIN_WIFI_EN 0u
#endif
#ifndef CC3501E_BRIDGE_PIN_NRST
#define CC3501E_BRIDGE_PIN_NRST 1u
#endif
/* OPTIONAL host-IRQ/READY input.  ready_pin has no fixed index or macro
 * here on purpose: on a board where the CC3501E's GPIO17 READY net is
 * actually routed to the host, set fw->ready_pin (in
 * cc3501e_bridge_bringup() below) to whatever Alif pin that board wires it
 * to.  When set, cc3501e_reply_gate() (chips/cc3501e/cc3501e_core.c) can
 * only ever ADD delay to a reply phase, never remove it, so opting in on a
 * board where the wiring is wrong costs up to 3 x 250 ms of busy-wait per
 * latch cycle before the driver's own (recoverable) stuck-LOW latch gives up
 * on it -- longer thresholds apply after each re-latch if the line flaps
 * instead of staying cleanly stuck (chips/cc3501e/cc3501e_core.c's
 * g_ready_stuck_low_threshold) -- it is always safe to try FOR LINK TIMING.
 * It is not free, though: this
 * wait runs while cc3501e_request() holds its internal transport lock, so
 * a wrong or slow ready_pin can make another caller on the same ctx see
 * ALP_ERR_BUSY after CONFIG_ALP_SDK_CC3501E_REQUEST_LOCK_TIMEOUT_MS -- see
 * <alp/chips/cc3501e/core.h>'s ready_pin doc.
 *
 * NOT Alif P2_6 on an R2 AEN EVK bench module: P2_6 there is E1M pad AH7 /
 * I2S1_SCLK (the EVK's Arduino CK_RST, metadata/boards/e1m-evk.yaml), and
 * the CC3501E GPIO17 READY net lands on E1M pad G3 / IO16 instead
 * (metadata/e1m_modules/aen/from-cc3501e.tsv).  cc3501e_bridge_bringup()
 * below leaves ready_pin NULL by default on that module -- see
 * cc3501e_reply_gate()'s own doc comment for the bench evidence. */

/* DW SSI SPI1 base (0x48104000) + RX_SAMPLE_DLY to run the bridge SCLK above
 * 1 MHz.  spi_dw_configure never writes RX_SAMPLE_DLY (0xf0), so without the
 * poke in cc3501e_bridge.c the master samples MISO at the SCLK edge, before the
 * on-SoM trace + crossed-data round-trip returns the CC35's bit, and anything
 * above 1 MHz mis-samples.  Setting it delays the capture by N ssi_clk
 * (200 MHz) cycles -- 5 ns per step.
 *
 * 4 is silicon-measured at the 25 MHz working point (40 ns bit period) on
 * a bench E1M-AEN803.  N was swept 0..10 with 0x481040F0 read back
 * each time to confirm the value took, using aen-evk-demo phase 8 as the
 * workload:
 *
 *   N = 0..7   PASS, 2-3 runs each: bring-up 0, PING on attempt 1 of 25,
 *              byte-exact MAC, scan 0, BLE 0.
 *   N = 8      FAIL, 3 runs of 3: bring-up still returns 0, but the link never
 *              answers -- PING -> -5 after all 25 attempts.
 *   N = 9      PASS, 2 runs of 2.
 *   N = 10     PASS, 3 runs of 3, but one run returned a MAC with a single bit
 *              flipped in byte 0.
 *
 * 4 is the centre of the measured-good 0..7 span: +4 steps (20 ns, half a bit
 * period) below the failure, and the low side is not a cliff at all since 0
 * itself is clean.  Do NOT read 8/9/10 as a monotone upper boundary -- 8
 * hard-fails while 9 and 10 pass, which this sweep did not explain.  Treat
 * everything above 7 as unqualified, not as graded margin.
 *
 * The "4..8 all clean cold+warm" window this comment used to claim was taken on
 * an earlier bench run at ~14.3 MHz -- a different board at roughly half the clock,
 * so it is not comparable and is not evidence for 25 MHz on this one.
 *
 * 0 does NOT mean "no delay": it compiles the poke out, leaving whatever the
 * SPI node's `rx-delay` property put there (see cc3501e_bridge.c).  Re-sweep if
 * the SoM trace lengths or the SCLK change. */
#ifndef CC3501E_BRIDGE_SPI1_BASE
#define CC3501E_BRIDGE_SPI1_BASE 0x48104000u
#endif
#ifndef CC3501E_BRIDGE_RX_SAMPLE_DLY
#define CC3501E_BRIDGE_RX_SAMPLE_DLY 4u
#endif

/**
 * @brief Bring up the SoM's CC3501E coprocessor over the inter-chip bridge.
 *
 * Opens the hardware-SS0 bridge SPI + the WIFI_EN / nRESET control pins, binds
 * them to @p fw, attaches the GPIO proxy (when CONFIG_ALP_SDK_GPIO_CC3501E_PROXY is
 * built), and runs the power + reset sequence (TI SWRU626 + the Puya cold-boot
 * hard-reset workaround).  Blocks ~900 ms for the boot budget; leaves WIFI_EN HIGH.
 *
 * @param fw  Caller-owned handle, populated on success.  Use it with cc3501e_*.
 * @return ALP_OK with @p fw ready; ALP_ERR_NOT_PRESENT_ON_THIS_SOC if the SPI bus /
 *         control pins are absent (check the board overlay); otherwise the reset
 *         sequence status.  On any failure @p fw is left un-bound (do not use it).
 */
alp_status_t cc3501e_bridge_bringup(cc3501e_t *fw);

#endif /* CC3501E_BRIDGE_H */
```
